# STM32MP13xx register map
File version: 1.5
CPU: CA7 r0p0, little endian, MPU, FPU, 4 interrupt priority bits
Registers are 32-bit, read-write, reset 0x0 unless marked. A register's access mark holds for its fields unless they carry their own. Offsets are from the block's base; [hi:lo] are bit positions; {n}, {i} and the like mark numbered series; 'fields as' and 'values as' point back to an identical list.

## RCC (part 1 of 7)
Base 0x50000000
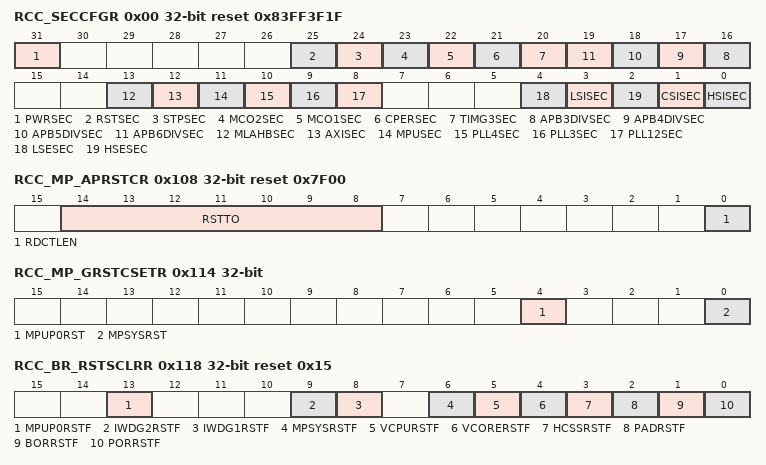
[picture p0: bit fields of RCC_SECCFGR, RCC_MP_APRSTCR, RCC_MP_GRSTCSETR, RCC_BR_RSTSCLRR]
0x00 RCC_SECCFGR reset 0x83FF3F1F — RCC secure configuration register
  [all] fields
    0=non-secure; 1=secure (default after reset)
  [31] PWRSEC — Secure state of the PWR block This control bit generates the output signal rcc_pwr_sec which is connected to the PWR block.
  [25] RSTSEC — Secure state of the reset
  [24] STPSEC — Secure state of the Stop modes
  [23] MCO2SEC — Secure state of the MCO2 clock
  [22] MCO1SEC — Secure state of the MCO1 clock
  [21] CPERSEC — Secure state of the common peripheral clock
  [20] TIMG3SEC — Secure state of the TIMG3 prescaler
  [n+13] APB{n}DIVSEC (n=3..6) — Secure state of the APB{n}DIV divider
  [13] MLAHBSEC — Secure state of the MLAHB sub-system clock
  [12] AXISEC — Secure state of the AXI sub-system clock
  [11] MPUSEC — Secure state of the MPU sub-system clock
  [10] PLL4SEC — Secure state of the PLL4 clock
  [9] PLL3SEC — Secure state of the PLL3 clock
  [8] PLL12SEC — Secure state of the PLL1 and PLL2 clocks
  [4] LSESEC — Secure state of the LSE clock
  [3] LSISEC — Secure state of the LSI clock
  [2] HSESEC — Secure state of the HSE clock
  [1] CSISEC — Secure state of the CSI clock
  [0] HSISEC — Secure state of the HSI clock
0x100 RCC_MP_SREQSETR — RCC stop request set register
  [0] STPREQ_P0 — Stop request from MPU processor Set by software Indicates if the MPU processor allow or not the entry in CStop/CStandby modes for MPU domain, when the MPU is in WFI. Note: the entry selection between CStop and CStandby is controlled by PWR_MPUCR.PDDS and PWR_CR1.STOP2 control bits.
    0=Writing '0' has no effect, reading '0' means that the MPU processor does not allow the MPU domain to go to CStop/CStandby; then if MPU is in WFI, it is kept in CSleep; 1=Writing '1' sets the STPREQ_P0 bit, reading '1' means that the MPU processor allows the MPU domain to go to CStop
0x104 RCC_MP_SREQCLRR — RCC stop request clear register
  [0] STPREQ_P0 — Stop request from MPU processor Cleared by software Indicates if the MPU processor allow or not the entry in CStop/CStandby modes for MPU domain, when the MPU is in WFI. Note: the entry selection between CStop and CStandby is controlled by PWR_MPUCR.PDDS and PWR_CR1.STOP2 control bits.
    0=Writing '0' has no effect, reading '0' means that the MPU processor does not allow the MPU domain to go to CStop/CStandby; then if MPU is in WFI, it is kept in CSleep; 1=Writing '1' clears the STPREQ_P0 bit, reading '1' means that the MPU processor allows the MPU domain to go to CStop
0x108 RCC_MP_APRSTCR reset 0x7F00 — RCC application reset control register
  [14:8] RSTTO — Reset timeout delay adjust
    0=The timeout function is disabled; 1=The timeout is set to 2 x 2HSIDIV us; 127=The timeout is set to 128 x 2HSIDIV us (default after reset)
  [0] RDCTLEN — Reset delay control enable Set and reset by software.
    0=The RDCTL control block is bypassed (default after reset); 1=The RDCTL control block is enabled
0x10C RCC_MP_APRSTSR ro — RCC application reset status register
  [14:8] RSTTOV — Reset timeout delay value Set by hardware in order to give the value of the timeout counter. This function is only available when the RDCTLEN = '1'. If RSTTOS = '0' it means that a timeout occurred.
0x110 RCC_PWRLPDLYCR — RCC low-power Stop modes delay control register
  [21:0] PWRLP_DLY — PWRLP_TEMPO value Written by software. This register contains the delay value to be observed before activating the PLLs and interconnect clocks, after one of the system Stop modes. The delay is counted with the HSI clock. The user has to take into account HSIDIV value. The delay value is given by the following formula: PWRLP_DLY[21:0] / FHSI ...
    0=the PWRLP_TEMPO delay is bypassed (default after reset); 1=a PWRLP_TEMPO delay of one period of HSI (at 64 MHz) is observed; 0x3FFFFF=a PWRLP_TEMPO delay of about 65.5 milliseconds is observed
0x114 RCC_MP_GRSTCSETR — RCC global reset control set register
  [4] MPUP0RST — MPU processor reset Set by software, cleared by hardware when the reset command is completed. Note that the Snoop Control Unit of the MPU (SCU) is not reset.
    0=Writing '0' has no effect, reading '0' means that the block reset is released; 1=Writing '1' generates a reset of the MPU processor 0, reading '1' means that the block reset is asserted
  [0] MPSYSRST — System reset Set by software, cleared by hardware.
    0=Writing '0' has no effect, reading '0' means that the block reset is released; 1=Writing '1' generates a system reset, see Figure 3
0x118 RCC_BR_RSTSCLRR reset 0x15 — RCC BOOTROM reset status clear register
  [13] MPUP0RSTF — MPU processor reset flag Cleared by software, set by hardware when a MPU processor reset occurred.
    0=Writing '0' has no effect, reading '0' means that no MPU processor reset occurred (default after nreset reset); 1=Writing '1' clears the MPUP0RSTF flag, reading '1' means that MPU processor reset occurred
  [9] IWDG2RSTF — IWDG2 reset flag Cleared by software, set by hardware when a IWDG2 reset occurred.
    0=Writing '0' has no effect, reading '0' means that no IWDG2 reset occurred (default after por_rst reset); 1=Writing '1' clears the IWDG2RSTF flag, reading '1' means that a IWDG2 reset occurred
  [8] IWDG1RSTF — IWDG1 reset flag Cleared by software, set by hardware when a IWDG1 reset occurred.
    0=Writing '0' has no effect, reading '0' means that no IWDG1 reset occurred (default after por_rst reset); 1=Writing '1' clears the IWDG1RSTF flag, reading '1' means that a IWDG1 reset occurred
  [6] MPSYSRSTF — MPU System reset flag Cleared by software, set by hardware when a MPU system reset occurred.
    0=Writing '0' has no effect, reading '0' means that no system reset generated by the MPU occurred (default after por_rst reset); 1=Writing '1' clears the MPSYSRSTF flag, reading '1' means that a system reset generated by the MPU occurred
  [5] VCPURSTF — VDDCPU reset flag Cleared by software, set by hardware when a reset occurred because VDDCPU is lower than the expected value.
    0=Writing '0' has no effect, reading '0' means that VDDCPU is not the origin of the reset; 1=Writing '1' clears the VCPURSTF flag, reading '1' means that VDDCPU is the origin of the reset (default after por_rst reset)
  [4] VCORERSTF — VDDCORE reset flag Cleared by software, set by hardware when a reset occurred because VDDCORE is lower than the expected value.
    0=Writing '0' has no effect, reading '0' means that VDDCORE is not the origin of the reset; 1=Writing '1' clears the VCORERSTF flag, reading '1' means that VDDCORE is the origin of the reset (default after por_rst reset)
  [3] HCSSRSTF — HSE CSS reset flag Cleared by software, set by hardware when a failure is detected on HSE.
    0=Writing '0' has no effect, reading '0' means that no HSE CSS reset occurred (default after por_rst reset); 1=Writing '1' clears the HCSSRSTF flag, reading '1' means that a HSE CSS reset occurred
  [2] PADRSTF — NRST reset flag Cleared by software, set by hardware when a PAD reset occurred.
    0=Writing '0' has no effect, reading '0' means that no PAD reset occurred (default after por_rst reset); 1=Writing '1' clears the PADRSTF flag, reading '1' means that a PAD reset occurred
  [1] BORRSTF — BOR reset flag Cleared by software, set by hardware when a BOR reset occurred.
    0=Writing '0' has no effect, reading '0' means that no BOR reset occurred (default after por_rst reset); 1=Writing '1' clears the BORRSTF flag, reading '1' means that a BOR reset occurred
  [0] PORRSTF — POR/PDR reset flag Cleared by software, set by hardware when a POR/PDR reset occurred.
    0=Writing '0' has no effect, reading '0' means that no POR/PDR reset occurred; 1=Writing '1' clears the PORRSTF flag, reading '1' means that a POR/PDR reset occurred (default after por_rst reset)
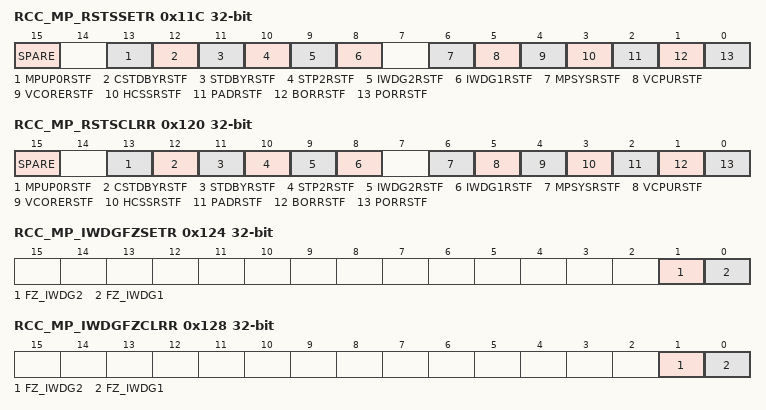
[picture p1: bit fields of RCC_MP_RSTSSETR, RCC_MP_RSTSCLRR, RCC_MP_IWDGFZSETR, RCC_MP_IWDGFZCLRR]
0x11C RCC_MP_RSTSSETR — RCC reset status set register
  [15] SPARE — Spare bit Set and reset by software. Reserved for future use.
  [13] MPUP0RSTF — MPU processor reset flag Set by the BOOTROM code when a MPU processor reset occurred.
    0=No MPU processor reset occurred (default after nreset reset); 1=MPU processor reset occurred
  [12] CSTDBYRSTF — MPU CStandby reset flag Set by the BOOTROM code when the MPU exits from CStandby.
    0=MPU has not been in CStandby; 1=MPU has been in CStandby
  [11] STDBYRSTF — System Standby reset flag Set by the BOOTROM code when exiting from Standby.
    0=System has not been in Standby mode; 1=System has been in Standby mode
  [10] STP2RSTF — Stop2 reset flag Set by the BOOTROM code when exiting from Stop2.
    0=System has not been in Stop2 mode; 1=System has been in Stop2 mode
  [9] IWDG2RSTF — IWDG2 reset flag Set by the BOOTROM code when a IWDG2 reset occurred.
    0=No IWDG2 reset occurred; 1=An IWDG2 reset occurred
  [8] IWDG1RSTF — IWDG1 reset flag Set by the BOOTROM code when a IWDG1 reset occurred.
    0=No IWDG1 reset occurred; 1=An IWDG1 reset occurred
  [6] MPSYSRSTF — MPU System reset flag Set by the BOOTROM code when a MPU system reset occurred.
    0=No system reset generated by the MPU occurred; 1=A system reset generated by the MPU occurred
  [5] VCPURSTF — VCPU reset flag Set by the BOOTROM code when a reset occurred because VCPU is lower than the expected value.
    0=VCPU is not the origin of the reset; 1=VCPU is the origin of the reset
  [4] VCORERSTF — VDDCORE reset flag Set by the BOOTROM code when a reset occurred because VDDCORE is lower than the expected value.
    0=VDDCORE is not the origin of the reset; 1=VDDCORE is the origin of the reset
  [3] HCSSRSTF — HSE CSS reset flag Set by the BOOTROM code when a failure is detected on HSE.
    0=No HSE CSS reset occurred; 1=A HSE CSS reset occurred
  [2] PADRSTF — NRST reset flag Set by the BOOTROM code when a PAD reset occurred.
    0=No PAD reset occurred; 1=A PAD reset occurred
  [1] BORRSTF — BOR reset flag Set by the BOOTROM code when a BOR reset occurred.
    0=No BOR reset occurred; 1=A BOR reset occurred
  [0] PORRSTF — POR/PDR reset flag Set by the BOOTROM code when a POR/PDR reset occurred.
    0=No POR/PDR reset occurred; 1=A POR/PDR reset occurred
0x120 RCC_MP_RSTSCLRR — RCC reset status clear register
  [15] SPARE — Spare bit Set and reset by software. Reserved for future use.
  [13] MPUP0RSTF — MPU processor reset flag Cleared by software, set by the BOOTROM code when a MPU processor reset occurred.
    values as RCC_MP_RSTSSETR.MPUP0RSTF
  [12] CSTDBYRSTF — MPU CStandby reset flag Cleared by software, set by the BOOTROM code when the MPU exits from CStandby.
    0=MPU has not been in CStandby mode; 1=MPU has been in CStandby mode
  [11] STDBYRSTF — System Standby reset flag Cleared by software, set by the BOOTROM code when exiting from Standby.
    values as RCC_MP_RSTSSETR.STDBYRSTF
  [10] STP2RSTF — Stop2 reset flag Cleared by software, set by the BOOTROM code when exiting from Stop2.
    values as RCC_MP_RSTSSETR.STP2RSTF
  [9] IWDG2RSTF — IWDG2 reset flag Cleared by software, set by the BOOTROM code when a IWDG2 reset occurred.
    0=No IWDG2 reset occurred; 1=An IWDG2 reset occurred
  [8] IWDG1RSTF — IWDG1 reset flag Cleared by software, set by the BOOTROM code when a IWDG1 reset occurred.
    0=No IWDG1 reset occurred; 1=An IWDG1 reset occurred
  [6] MPSYSRSTF — MPU System reset flag Cleared by software, set by the BOOTROM code when a MPU system reset occurred.
    values as RCC_MP_RSTSSETR.MPSYSRSTF
  [5] VCPURSTF — VDDCPU reset flag Cleared by software, set by the BOOTROM code when a reset occurred because VDDCPU is lower than the expected value.
    0=VDDCPU is not the origin of the reset; 1=VDDCPU is the origin of the reset
  [4] VCORERSTF — VDDCORE reset flag Cleared by software, set by the BOOTROM code when a reset occurred because VDDCORE is lower than the expected value.
    values as RCC_MP_RSTSSETR.VCORERSTF
  [3] HCSSRSTF — HSE CSS reset flag Cleared by software, set by the BOOTROM code when a failure is detected on HSE.
    0=No HSE CSS reset occurred; 1=A HSE CSS reset occurred
  [2] PADRSTF — NRST reset flag Cleared by software, set by the BOOTROM code when a PAD reset occurred.
    0=No PAD reset occurred; 1=A PAD reset occurred
  [1] BORRSTF — BOR reset flag Cleared by software, set by the BOOTROM code when a BOR reset occurred.
    0=No BOR reset occurred; 1=A BOR reset occurred
  [0] PORRSTF — POR/PDR reset flag Cleared by software, set by the BOOTROM code when a POR/PDR reset occurred.
    0=No POR/PDR reset occurred; 1=A POR/PDR reset occurred
0x124 RCC_MP_IWDGFZSETR — RCC IWDG clock freeze set register
  [1] FZ_IWDG2 — Freeze the IWDG2 clock Set once by the BOOTROM software after a system reset or Standby reset, or a CStandby reset, in order to freeze the IWDG2.
    0=Writing '0' has no effect, reading '0' means that the IWDG2 clock is not frozen (default after reset); 1=Writing '1' freeze the IWDG2 clock, reading '1' means that the IWDG2 clock is frozen
  [0] FZ_IWDG1 — Freeze the IWDG1 clock If IWDG1 block is configured as secure via the corresponding DECPROT[1] field of the ETZPC register, a write access to this register field must be secure. A read access may be secure or non-secure. Set once by the BOOTROM software after a system reset or Standby reset, or a CStandby reset, in order to freeze the IWDG1.
    0=Writing '0' has no effect, reading '0' means that the IWDG1 clock is not frozen (default after reset); 1=Writing '1' freeze the IWDG1 clock, reading '1' means that the IWDG1 clock is frozen
0x128 RCC_MP_IWDGFZCLRR — RCC IWDG clock freeze clear register
  [1] FZ_IWDG2 — Unfreeze the IWDG2 clock Cleared by the BOOTROM software, in order to unfreeze the IWDG2.
    0=Writing '0' has no effect, reading '0' means that the IWDG2 clock is not frozen (default after reset); 1=Writing '1' unfreeze the IWDG2 clock, reading '1' means that the IWDG2 clock is frozen
  [0] FZ_IWDG1 — Unfreeze the IWDG1 clock If IWDG1 block is configured as secure via the corresponding DECPROT[1] field of the ETZPC register, a write access to this register field must be secure. A read access may be secure or non-secure. Cleared by the BOOTROM software, in order to unfreeze the IWDG1.
    0=Writing '0' has no effect, reading '0' means that the IWDG1 clock is not frozen (default after reset); 1=Writing '1' unfreeze the IWDG1 clock, reading '1' means that the IWDG1 clock is frozen
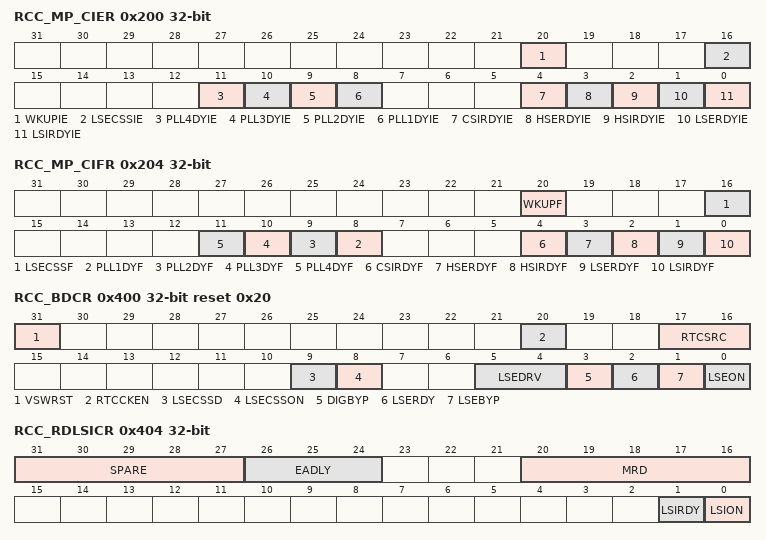
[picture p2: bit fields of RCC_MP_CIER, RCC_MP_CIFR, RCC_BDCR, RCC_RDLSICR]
0x200 RCC_MP_CIER — RCC clock source interrupt enable register
  [20] WKUPIE — Wake up from CStop Interrupt Enable If RCC_SECCFGR.STPSEC, a write access to this field must be secure. A read access may be secure or non-secure. Set and reset by software to enable/disable the generation of the interrupt used to wake up the MPU from CStop.
    0=Wakeup interrupt disabled (default after reset); 1=Wakeup interrupt enabled
  [16] LSECSSIE — LSE clock security system Interrupt Enable If RCC_SECCFGR.LSESEC, a write access to this field must be secure. A read access may be secure or non-secure. Set and reset by software to enable/disable interrupt caused by the Clock Security System on external 32 kHz oscillator.
    0=LSE CSS interrupt disabled (default after reset); 1=LSE CSS interrupt enabled
  [11] PLL4DYIE — PLL4 ready Interrupt Enable If RCC_SECCFGR.PLL4SEC, a write access to this field must be secure. A read access may be secure or non-secure. Set and reset by software to enable/disable interrupt caused by PLL4 lock.
    0=PLL4 lock interrupt disabled (default after reset); 1=PLL4 lock interrupt enabled
  [10] PLL3DYIE — PLL3 ready Interrupt Enable If RCC_SECCFGR.PLL3SEC, a write access to this field must be secure. A read access may be secure or non-secure. Set and reset by software to enable/disable interrupt caused by PLL3 lock.
    0=PLL3 lock interrupt disabled (default after reset); 1=PLL3 lock interrupt enabled
  [9] PLL2DYIE — PLL2 ready Interrupt Enable If RCC_SECCFGR.PLL12SEC, a write access to this field must be secure. A read access may be secure or non-secure. Set and reset by software to enable/disable interrupt caused by PLL2 lock.
    0=PLL2 lock interrupt disabled (default after reset); 1=PLL2 lock interrupt enabled
  [8] PLL1DYIE — PLL1 ready Interrupt Enable If RCC_SECCFGR.PLL12SEC, a write access to this field must be secure. A read access may be secure or non-secure. Set and reset by software to enable/disable interrupt caused by PLL1 lock.
    0=PLL1 lock interrupt disabled (default after reset); 1=PLL1 lock interrupt enabled
  [4] CSIRDYIE — CSI ready Interrupt Enable If RCC_SECCFGR.CSISEC, a write access to this field must be secure. A read access may be secure or non-secure. Set and reset by software to enable/disable interrupt caused by the CSI oscillator stabilization.
    0=CSI ready interrupt disabled (default after reset); 1=CSI ready interrupt enabled
  [3] HSERDYIE — HSE ready Interrupt Enable If RCC_SECCFGR.HSESEC, a write access to this field must be secure. A read access may be secure or non-secure. Set and reset by software to enable/disable interrupt caused by the HSE oscillator stabilization.
    0=HSE ready interrupt disabled (default after reset); 1=HSE ready interrupt enabled
  [2] HSIRDYIE — HSI ready Interrupt Enable If RCC_SECCFGR.HSISEC, a write access to this field must be secure. A read access may be secure or non-secure. Set and reset by software to enable/disable interrupt caused by the HSI oscillator stabilization.
    0=HSI ready interrupt disabled (default after reset); 1=HSI ready interrupt enabled
  [1] LSERDYIE — LSE ready Interrupt Enable If RCC_SECCFGR.LSESEC, a write access to this field must be secure. A read access may be secure or non-secure. Set and reset by software to enable/disable interrupt caused by the LSE oscillator stabilization.
    0=LSE ready interrupt disabled (default after reset); 1=LSE ready interrupt enabled
  [0] LSIRDYIE — LSI ready Interrupt Enable If RCC_SECCFGR.LSISEC, a write access to this field must be secure. A read access may be secure or non-secure. Set and reset by software to enable/disable interrupt caused by the LSI oscillator stabilization.
    0=LSI ready interrupt disabled (default after reset); 1=LSI ready interrupt enabled
0x204 RCC_MP_CIFR — RCC clock source interrupt flag register
  [20] WKUPF — Wake up from CStop Interrupt Flag If RCC_SECCFGR.STPSEC, a write access to this field must be secure. A read access may be secure or non-secure. Reset by software by writing this flag to '1'. Set by hardware when the MPU needs to exit from CStop.
    0=No wakeup interrupt pending (default after reset); 1=Wakeup interrupt pending, writing '1' clears this flag
  [16] LSECSSF — LSE clock security system Interrupt Flag If RCC_SECCFGR.LSESEC, a write access to this field must be secure. A read access may be secure or non-secure. Reset by software by writing this flag to '1'. Set by hardware when a failure is detected on the external 32 kHz oscillator.
    0=No failure detected on the external 32 kHz oscillator (default after reset); 1=A failure is detected on the external 32 kHz oscillator, writing '1' clears this flag
  [n+7] PLL{n}DYF (n=1..4) — PLL{n} ready Interrupt Flag If RCC_SECCFGR.PLLSEC, a write access to this field must be secure. A read access may be secure or non-secure. Reset by software by writing this flag to '1'. Set by hardware when the PLL{n} locks.
    0=No clock ready interrupt caused by PLL{n} lock (default after reset); 1=Clock ready interrupt caused by PLL{n} lock, writing '1' clears this flag
  [4] CSIRDYF — CSI ready Interrupt Flag If RCC_SECCFGR.PLLSEC, a write access to this field must be secure. A read access may be secure or non-secure. Reset by software by writing this flag to '1'. Set by hardware when the CSI clock becomes stable.
    0=No clock ready interrupt caused by the CSI (default after reset); 1=Clock ready interrupt caused by the CSI, writing '1' clears this flag
  [3] HSERDYF — HSE ready Interrupt Flag If RCC_SECCFGR.PLLSEC, a write access to this field must be secure. A read access may be secure or non-secure. Reset by software by writing this flag to '1'. Set by hardware when the HSE clock becomes stable.
    0=No clock ready interrupt caused by the HSE (default after reset); 1=Clock ready interrupt caused by the HSE, writing '1' clears this flag
  [2] HSIRDYF — HSI ready Interrupt Flag If RCC_SECCFGR.PLLSEC, a write access to this field must be secure. A read access may be secure or non-secure. Reset by software by writing this flag to '1'. Set by hardware when the HSI clock becomes stable.
    0=No clock ready interrupt caused by the HSI (default after reset); 1=Clock ready interrupt caused by the HSI, writing '1' clears this flag
  [1] LSERDYF — LSE ready Interrupt Flag If RCC_SECCFGR.PLLSEC, a write access to this field must be secure. A read access may be secure or non-secure. Reset by software by writing this flag to '1'. Set by hardware when the LSE clock becomes stable.
    0=No clock ready interrupt caused by the LSE (default after reset); 1=Clock ready interrupt caused by the LSE, writing '1' clears this flag
  [0] LSIRDYF — LSI ready Interrupt Flag If RCC_SECCFGR.PLLSEC, a write access to this field must be secure. A read access may be secure or non-secure. Reset by software by writing this flag to '1'. Set by hardware when the LSI clock becomes stable.
    0=No clock ready interrupt caused by the LSI (default after reset); 1=Clock ready interrupt caused by the LSI, writing '1' clears this flag
0x400 RCC_BDCR access per field reset 0x20 — RCC backup domain control register
  [31] VSWRST rw — VSW domain software reset Set and reset by software. If RCC_SECCFGR.RSTSEC, a write access to this field must be secure. A read access may be secure or non-secure.
    0=write: release the software reset; read: software reset not activated (default after backup domain reset); 1=write: reset the entire VSW domain; read: software reset activated
  [20] RTCCKEN rw — RTC clock enable Set and reset by software. If at least one function of the RTC is configured as secure via the RTC_SECCFGR register (i.e. if the input signal rtc_sec driven by RTC is asserted), a write access to this register field must be secure. A read access may be secure or non-secure.
    0=rtc_ck clock is disabled (default after backup domain reset); 1=rtc_ck clock enabled
  [17:16] RTCSRC rw — RTC clock source selection Set by software to select the clock source for the RTC. If at least one function of the RTC is configured as secure via the RTC_SECCFGR register (i.e. if the input signal rtc_sec driven by RTC is asserted), a write access to this register field must be secure. A read access may be secure or non-secure. This field can be written only one time after backup domain reset. When a LSE failure occurs, the RTCSRC[1:0] is set to '00', and the software is allowed to write it again once. This field must be written before LSECSSON is enabled. Refer to for details.
    0=No clock (default after backup domain reset); 1=LSE clock used as RTC clock; 2=LSI clock used as RTC clock; 3=HSE clock divided by RTCDIV value is used as RTC clock
  [9] LSECSSD ro — LSE clock security system failure detection Set by hardware to indicate when a failure has been detected by the Clock Security System on the external 32 kHz oscillator.
    0=No failure detected on 32 kHz oscillator (default after backup domain reset); 1=Failure detected on 32 kHz oscillator
  [8] LSECSSON rw — LSE clock security system enable Set by software to enable the Clock Security System on 32 kHz oscillator. If RCC_SECCFGR.LSESEC, a write access to this register field must be secure. A read access may be secure or non-secure. Refer to for details on the activation and deactivation sequences. Once the LSECSSON bit is enabled it cannot be disabled, except after a LSE failure detection (LSECSSD = '1').
    0=Clock Security System on 32 kHz oscillator OFF (default after backup domain reset); 1=Clock Security System on 32 kHz oscillator ON
  [5:4] LSEDRV rw — LSE oscillator driving capability Written by software to select the driving capability of the LSE oscillator. If RCC_SECCFGR.LSESEC, a write access to this register field must be secure. A read access may be secure or non-secure.
    0=Lowest drive; 1=Medium low drive; 2=Medium high drive (default after backup domain reset); 3=Highest drive
  [3] DIGBYP rw — LSE digital bypass Set and reset by software to select the analog or digital bypass mode. If RCC_SECCFGR.LSESEC, a write access to this register field must be secure. A read access may be secure or non-secure.
    0=The LSE is in analog bypass mode (default after backup domain reset); 1=The LSE is in digital bypass mode
  [2] LSERDY ro — LSE oscillator ready Set and reset by hardware to indicate when the LSE is stable. This bit needs 6 cycles of lse_ck clock to fall down after LSEON has been set to '0'.
    0=LSE oscillator not ready (default after backup domain reset); 1=LSE oscillator ready
  [1] LSEBYP rw — LSE oscillator bypass Set and reset by software to bypass oscillator in debug mode. If RCC_SECCFGR.LSESEC, a write access to this register field must be secure. A read access may be secure or non-secure. This bit must not be written when the LSE is enabled (LSEON = '1'). Refer to Stop. for details.
    0=LSE oscillator not bypassed (default after backup domain reset); 1=LSE oscillator bypassed
  [0] LSEON rw — LSE oscillator enabled Set and reset by software. If RCC_SECCFGR.LSESEC, a write access to this register field must be secure. A read access may be secure or non-secure.
    0=LSE oscillator OFF (default after backup domain reset); 1=LSE oscillator ON
0x404 RCC_RDLSICR access per field — RCC reset duration and LSI control register
  [31:27] SPARE rw — Spare bits Written by software. If RCC_SECCFGR.RSTSEC, a write access to this field must be secure. A read access may be secure or non-secure. Reserved for future use.
  [26:24] EADLY rw — External access delays Written by software. If RCC_SECCFGR.RSTSEC, a write access to this field must be secure. A read access may be secure or non-secure. Time to wait before the BOOTROM performs any external access (UART, USB, QUADSPI, FMC, SDMMC,...)
    0=10 ms (default after reset); 1=No extra delay added by the BOOTROM; 2=100 us; 3=200 us; 4=500 us; 5=1 ms; 6=2 ms; 7=5 ms
  [20:16] MRD rw — Minimum reset duration Written by software. If RCC_SECCFGR.RSTSEC, a write access to this field must be secure. A read access may be secure or non-secure. This field defines the minimum guaranteed duration of the NRST low pulse. The LSI oscillator is automatically enabled when needed by the RPCTL. ...
    0=NRST low pulse duration is guaranteed by the pulse stretcher of the PAD. The RPCTL is bypassed (default after reset); 1=The guaranteed NRST low pulse duration is about 1 ms (1 x 32 lsi_ck cycles),; 2=The guaranteed NRST low pulse duration is about 2 ms (2 x 32 lsi_ck cycles),; 31=The guaranteed NRST low pulse duration is about 31 ms (31 x 32 lsi_ck cycles)
  [1] LSIRDY ro — LSI oscillator ready Set and reset by hardware to indicate when the LSI is stable. This bit needs 3 cycles of lsi_ck clock to fall down after LSION has been set to '0'.
    0=LSI oscillator not ready (default after reset); 1=LSI oscillator ready
  [0] LSION rw — LSI oscillator enabled Set and reset by software. If RCC_SECCFGR.LSISEC, a write access to this field must be secure. A read access may be secure or non-secure. This bit is used to request the activation of the LSI oscillator. Note that IWDG1 and IWDG2 can also request the activation of LSI.
    0=LSI oscillator is OFF if no other requester needs it, such as IWDG[2:1] (default after reset); 1=LSI oscillator ON
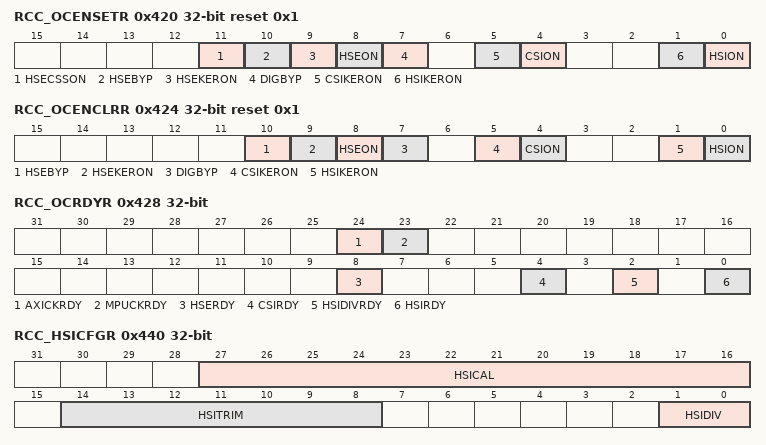
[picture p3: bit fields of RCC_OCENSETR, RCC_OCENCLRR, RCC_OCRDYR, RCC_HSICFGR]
0x420 RCC_OCENSETR reset 0x1 — RCC oscillator clock enable set register
  [11] HSECSSON — Set the HSECSSON bit
    0=Reading '0' means that the Clock Security System on HSE is OFF (default after reset); 1=Writing '1' enables the Clock Security System on HSE, reading '1' means that the Clock Security System on HSE is ON
  [10] HSEBYP — Set HSEBYP bit Set by software in order to enable the bypass mode. This bit must be written by a secure agent if the HSE clock is configured as secure (i.e. if RCC_SECCFGR.HSESEC=1).
    0=No effect; 1=Set the HSEBYP bit
  [9] HSEKERON — Set HSEKERON bit Set by software to force the HSE to ON, even in (LP-)Stop mode, in order to be quickly available as kernel clock for some peripherals. This bit must be written by a secure agent if the HSE clock is configured as secure (i.e. if RCC_SECCFGR.HSESEC=1). This bit has no effect on the value of HSEON.
    0=No effect; 1=Set the HSEKERON bit
  [8] HSEON — Set HSEON bit Set by software to enable the HSE. This bit must be written by a secure agent if the HSE clock is configured as secure (i.e. if RCC_SECCFGR.HSESEC=1).
    0=No effect; 1=Set HSEON bit
  [7] DIGBYP — Set DIGBYP bit Set by software when the external HSE clock is connected to OSC_IN as a full-swing digital signal. This bit must be written by a secure agent if the HSE clock is configured as secure (i.e. if RCC_SECCFGR.HSESEC=1).
    0=No effect; 1=Set DIGBYP bit (digital bypass)
  [5] CSIKERON — Set CSIKERON bit Set by software to force the CSI to ON, even in (LP-)Stop mode, in order to be quickly available as kernel clock for some peripherals. This bit must be written by a secure agent if the CSI clock is configured as secure (i.e. if RCC_SECCFGR.CSISEC=1). This bit has no effect on the value of CSION.
    0=No effect; 1=Set the CSIKERON bit
  [4] CSION — Set CSION bit Set by software to enable CSI clock. This bit must be written by a secure agent if the CSI clock is configured as secure (i.e. if RCC_SECCFGR.CSISEC=1).
    0=No effect; 1=Set the CSION bit
  [1] HSIKERON — Set HSIKERON bit Set by software to force the HSI to ON, even in (LP-)Stop mode, in order to be quickly available as kernel clock for peripherals. This bit must be written by a secure agent if the HSI clock is configured as secure (i.e. if RCC_SECCFGR.HSISEC=1). This bit has no effect on the value of HSION.
    0=No effect; 1=Set the HSIKERON bit
  [0] HSION — Set HSION bit Set by software to enable the HSI clock. This bit must be written by a secure agent if the HSI clock is configured as secure (i.e. if RCC_SECCFGR.HSISEC=1). The HSION is also set by hardware to force the HSI to ON when the product leaves Standby mode or one of the Stop modes.
    0=No effect; 1=Set the HSION bit
0x424 RCC_OCENCLRR reset 0x1 — RCC oscillator clock enable clear register
  [10] HSEBYP — Clear the HSEBYP bit Cleared by software in order to disable the bypass mode. This bit must be written by a secure agent if the HSE clock is configured as secure (i.e. if RCC_SECCFGR.HSESEC=1).
    0=No effect; 1=Clear the HSEBYP bit
  [9] HSEKERON — Clear HSEKERON bit Cleared by software in order to allow the HSE to be switched off in one of the Stop modes. This bit must be written by a secure agent if the HSE clock is configured as secure (i.e. if RCC_SECCFGR.HSESEC=1).
    0=No effect; 1=Clear the HSEKERON bit
  [8] HSEON — Clear of HSEON bit Cleared by software to disable the HSE clock. This bit must be written by a secure agent if the HSE clock is configured as secure (i.e. if RCC_SECCFGR.HSESEC=1).
    0=No effect; 1=Clear the HSEON bit
  [7] DIGBYP — Clear of DIGBYP bit Cleared by software when the external clock connected to OSC_IN is a low-swing signal. This bit must be written by a secure agent if the HSE clock is configured as secure (i.e. if RCC_SECCFGR.HSESEC=1).
    0=No effect; 1=Clear the DIGBYP bit (analog bypass)
  [5] CSIKERON — Clear of CSIKERON bit Cleared by software in order to allow the CSI to be switched off in one of the Stop modes. This bit must be written by a secure agent if the CSI clock is configured as secure (i.e. if RCC_SECCFGR.CSISEC=1). This bit has no effect on the value of CSION.
    0=No effect; 1=Clear the CSIKERON bit
  [4] CSION — Clear of CSION bit Cleared by software to disable the CSI clock. This bit must be written by a secure agent if the CSI clock is configured as secure (i.e. if RCC_SECCFGR.CSISEC=1).
    0=CSI is OFF; 1=Clear the CSION bit
  [1] HSIKERON — Clear of HSIKERON bit Cleared by software in order to allow the HSI to be switched off in one of the Stop modes. This bit must be written by a secure agent if the HSI clock is configured as secure (i.e. if RCC_SECCFGR.HSISEC=1). This bit has no effect on the value of HSION.
    0=No effect; 1=Clear the HSIKERON bit
  [0] HSION — Clear of HSION bit Cleared by software to disable the HSI clock. This bit must be written by a secure agent if the HSI clock is configured as secure (i.e. if RCC_SECCFGR.HSISEC=1).
    0=No effect; 1=Clear the HSION bit
0x428 RCC_OCRDYR ro — RCC oscillators and MPU and AXI clock ready register
  [24] AXICKRDY — AXI sub-system clock ready flag Set by hardware to indicate that the axiss_ck clock is available.
    0=axiss_ck clock is not available (default after reset); 1=axiss_ck clock is available
  [23] MPUCKRDY — MPU clock ready flag Set by hardware to indicate that the mpuss_ck clock is available.
    0=mpuss_ck clock is not available (default after reset); 1=mpuss_ck clock is available
  [8] HSERDY — HSE clock ready flag Set by hardware to indicate that the HSE oscillator is stable.
    0=HSE clock is not ready (default after reset); 1=HSE clock is ready
  [4] CSIRDY — CSI clock ready flag Set by hardware to indicate that the CSI oscillator is stable.
    0=CSI clock is not ready (default after reset); 1=CSI clock is ready
  [2] HSIDIVRDY — HSI divider ready flag Set and reset by hardware. As a write in HSIDIV has not an immediate effect on the frequency, this flag indicates the current status of the HSI divider. HSIDIVF will go immediately to '0' when HSIDIV value is changed, and will be set back to '1' when the output frequency matches the value programmed into HSIDIV
    0=the new division ratio is not yet propagated to hsi_ck (hsi_ker_ck) (default after reset); 1=the hsi_ck (hsi_ker_ck) clock frequency reflects the new HSIDIV value
  [0] HSIRDY — HSI clock ready flag Set by hardware to indicate that the HSI oscillator is stable.
    0=HSI clock is not ready (default after reset); 1=HSI clock is ready
0x440 RCC_HSICFGR access per field — RCC HSI configuration register
  [27:16] HSICAL ro — HSI clock calibration Set by hardware by option byte loading during system reset Adjusted by software through trimming bits HSITRIM. This field represents the sum of engineering Option Byte calibration value and HSITRIM bits value.
  [14:8] HSITRIM rw — HSI clock trimming Set by software to adjust calibration. HSITRIM represents a signed value. HSITRIM field is added to the engineering Option Bytes loaded during reset phase (bsec_hsi_cal[11:0]) in order to form the calibration trimming value. HSICAL[11:0] = HSITRIM[6:0] + bsec_hsi_cal[11:0]. ... ...
    64=bsec_hsi_cal[11:0] - 64; 65=bsec_hsi_cal[11:0] - 63; 0=bsec_hsi_cal[11:0] (default after reset); 62=bsec_hsi_cal[11:0] + 62; 63=bsec_hsi_cal[11:0] + 63
  [1:0] HSIDIV rw — HSI clock divider Written by software. These bits allows the user to select a division ratio in order to select the wanted HSI clock frequency. The bit HSIDIVRDY of (RCC_OCRDYR) indicates when the new division ratio is taken into account.
    0=Division by 1, hsi_ck (hsi_ker_ck) = 64 MHz (default after reset); 1=Division by 2, hsi_ck (hsi_ker_ck) = 32 MHz; 2=Division by 4, hsi_ck (hsi_ker_ck) = 16 MHz; 3=Division by 8, hsi_ck (hsi_ker_ck) = 8 MHz
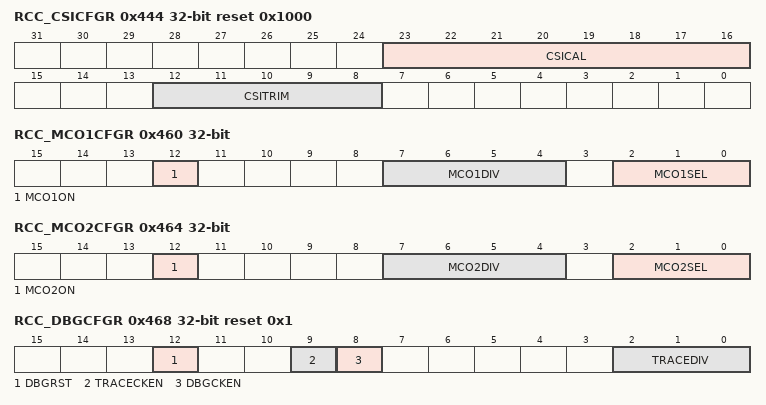
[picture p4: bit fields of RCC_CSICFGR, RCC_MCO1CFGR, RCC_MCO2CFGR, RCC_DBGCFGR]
0x444 RCC_CSICFGR access per field reset 0x1000 — RCC CSI configuration register
  [23:16] CSICAL ro — CSI clock calibration Set by hardware by option byte loading during system reset. Adjusted by software through trimming bits CSITRIM. This field represents the sum of engineering Option Byte calibration value and CSITRIM bits value
  [12:8] CSITRIM rw — CSI clock trimming Set by software to adjust calibration. CSITRIM field is added to the engineering Option Bytes loaded during reset phase (bsec_csi_cal[7:0]) in order to form the calibration trimming value. CSICAL[7:0] = CSITRIM[4:0] + bsec_csi_cal[7:0].
0x460 RCC_MCO1CFGR — RCC MCO1 configuration register
  [12] MCO1ON — Control of the MCO1 output Set and cleared by software to enable the MCO1 output
    0=The MCO1 output is disabled; 1=The MCO1 output is enabled
  [7:4] MCO1DIV — MCO1 prescaler Set and cleared by software to configure the prescaler of the MCO1. Modification of this prescaler may generate glitches on MCO1. It is highly recommended to change this prescaler only after reset, before enabling the external oscillators and the PLLs. Refer to for details. ...
    0=bypass (default after reset); 1=division by 2; 2=division by 3; 15=division by 16
  [2:0] MCO1SEL — MCO1 clock output selection Set and cleared by software. Clock source selection may generate glitches on MCO1. It is highly recommended to configure these bits only after reset, before enabling the external oscillators and the PLLs. others: reserved
    0=HSI clock selected (hsi_ck) (default after reset); 1=HSE clock selected (hse_ck); 2=CSI clock selected (csi_ck); 3=LSI clock selected (lsi_ck); 4=LSE oscillator clock selected (lse_ck)
0x464 RCC_MCO2CFGR — RCC MCO2 configuration register
  [12] MCO2ON — Control of the MCO2 output Set and cleared by software to enable the MCO2 output
    0=The MCO2 output is disabled; 1=The MCO2 output is enabled
  [7:4] MCO2DIV — MCO2 prescaler Set and cleared by software to configure the prescaler of the MCO2. Modification of this prescaler may generate glitches on MCO2. It is highly recommended to change this prescaler only after reset, before enabling the external oscillators and the PLLs. Refer to Section1.4.4: Clock Output generation (MCO1 & MCO2) for details. ...
    values as RCC_MCO1CFGR.MCO1DIV
  [2:0] MCO2SEL — Micro-controller clock output 2 Set and cleared by software. Clock source selection may generate glitches on MCO2. It is highly recommended to configure these bits only after reset, before enabling the external oscillators and the PLLs. others: reserved
    0=MPU clock selected (mpuss_ck) (default after reset); 1=AXI clock selected (axiss_ck); 2=MLAHB clock selected (mlahbss_ck); 3=PLL4 clock selected (pll4_p_ck); 4=HSE clock selected (hse_ck); 5=HSI clock selected (hsi_ck)
0x468 RCC_DBGCFGR reset 0x1 — RCC debug configuration register
  [12] DBGRST — Reset of the debug function Set and cleared by software to control the generation of the reset (dbg_rstn) for the trace and debug parts.
    0=The trace and debug parts are not reset. (default after reset); 1=The trace and debug parts are under reset
  [9] TRACECKEN — Clock enable for trace function Set and cleared by software to control the generation of the trace_ck clock. See for additional information.
    0=The clock for the trace function is disabled (default after reset); 1=The clock for the trace function is enabled
  [8] DBGCKEN — Clock enable for debug function Set and cleared by software to control the generation of the ck_apb_dbg clock (DEBUG APB clock), the ck_sys_dbg. See for additional information.
    0=The enabling of the clock for the debug function is controlled by cdbgwrupreq signal from DAP. (default after reset); 1=The clock for the debug function is enabled
  [2:0] TRACEDIV — Clock divider for the trace clock (ck_trace) Written by software to control the ck_trace clock division factor. It is possible to change this division ratio on-the-fly. others: aclk / 16
    0=aclk; 1=aclk / 2 (default after reset); 2=aclk / 4; 3=aclk / 8
